# timers: IP-XACT component
VLNV spiritconsortium.org:Leon2RTL:timers:1.3
Dual timer with enhanced register description using register files

## Parameters
TPRESC = 22

## Bus interfaces (logical=physical port)
APBClk: slave spiritconsortium.org:busdef.clock:clock:1.0
  CLK=clk
APBReset: slave spiritconsortium.org:busdef.reset:reset:1.0
  RESETn=rst
ambaAPB: slave amba.com:AMBA2:APB:r2p0_4, memory map ambaAPB
  PSELx=psel, PENABLE=penable, PADDR=paddr, PWRITE=pwrite, PWDATA=pwdata, PRDATA=prdata, PCLK=clk, PRESETn=rst
Int0: master spiritconsortium.org:busdef.interrupt:interrupt:1.0
  IRQ=irq0
Int1: master spiritconsortium.org:busdef.interrupt:interrupt:1.0
  IRQ=irq1

## Ports
in clk
in rst
in psel
in penable
in paddr[31:0]
in pwrite
in pwdata[31:0]
out prdata[31:0]
out irq0
out irq1
out tick
out wdog
in dsuact
in ntrace
in freezetime
in lresp
in dresp
in dsuen
in dsubre

## Address spaces and blocks
ambaAPB.defaultid4489914: base 0, range 0x28, width 32

## Registers
Registers are 32-bit, read-write, reset 0x0 unless marked. A register's access mark holds for its fields unless they carry their own. Offsets are from the block's base; lines under a group give offsets from that group; [hi:lo] are bit positions; {n}, {i} and the like mark numbered series; 'fields as' and 'values as' point back to an identical list; <NAME> marks a mode.

## ambaAPB.defaultid4489914
Base 0x00000000
0x00 timer1 group
  0x00 timerCounter (reset mask 0xFF000000) — Timer value
    [23:0] timerValue — Value of Timer
  0x04 timerReload (reset mask 0xFF000000) — Timer Reload Value
    [23:0] timerReloadValue
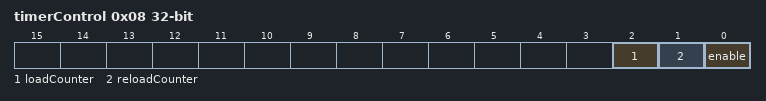
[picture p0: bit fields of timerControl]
  0x08 timerControl (reset mask 0xFFFFFFF9)
    [2] loadCounter write-1-clears — When written with 1, will load the timer reload register into the timer counter register. Always reads as a 0.
    [1] reloadCounter — When set to 1 the counter will automatically be reloaded with the reload value after each underflow.
    [0] enable — Enables the timer when set.
0x0C watchdogCounter (reset mask 0xFF000000) — Watchdog 1 value
  [23:0] watchdogValue
0x10 timer2 group
  0x00 timerCounter (reset mask 0xFF000000) — Timer value
    [23:0] timerValue — Value of Timer
  0x04 timerReload (reset mask 0xFF000000) — Timer Reload Value
    [23:0] timerReloadValue
  0x08 timerControl (reset mask 0xFFFFFFF9)
    [2] loadCounter write-1-clears — When written with 1, will load the timer reload register into the timer counter register. Always reads as a 0.
    [1] reloadCounter — When set to 1 the counter will automatically be reloaded with the reload value after each underflow.
    [0] enable — Enables the timer when set.
      1=TIMERENABLED; 1=ENABLETIMER; 0=TIMERDISABLED; 0=DISABLETIMER
0x20 prescalerCounter (reset mask 0xFFFFFC00)
  [9:0] reloadValue — Prescaler Counter Value
0x24 prescalerReloadValue (reset mask 0xFFFFFC00)
  [9:0] reloadValue

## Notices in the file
Copyright (c) 2006, 2008, 2009 The SPIRIT Consortium.
This work forms part of a deliverable of The SPIRIT Consortium.
Use of these materials are governed by the legal terms and conditions
outlined in the disclaimer available from www.spiritconsortium.org.
This source file is provided on an AS IS basis.  The SPIRIT
Consortium disclaims any warranty express or implied including
any warranty of merchantability and fitness for use for a
particular purpose.
The user of the source file shall indemnify and hold The SPIRIT
Consortium and its members harmless from any damages or liability.
